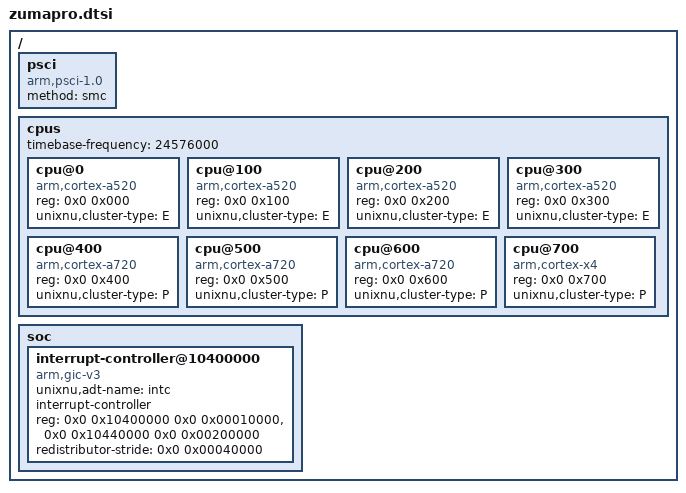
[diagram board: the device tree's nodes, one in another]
/*
 * Google Tensor G4 (zumapro).
 *
 * What is true of the chip. A board includes this and adds its own memory
 * range, framebuffer and peripherals.
 *
 * Every value was read from a Pixel 10a running stock Android, from its own
 * device tree or from the chip's registers by firmware running on it.
 */

/ {
    #address-cells = <2>;
    #size-cells = <2>;

    /* Cores are started through the secure monitor. */
    psci {
        compatible = "arm,psci-1.0";
        method = "smc";
    };

    cpus {
        #address-cells = <2>;
        #size-cells = <0>;

        /*
         * 24.576 MHz. Qualcomm boards, which most of this ecosystem is, run
         * at 19.2 MHz. A kernel told the wrong rate gets every timeout wrong
         * by a quarter and never says so.
         */
        timebase-frequency = <24576000>;

        /*
         * Four efficiency cores then four performance cores, at the affinity
         * values the phone reports. The capacities it publishes, 193 for the
         * first four and 927 or 1024 for the rest, are what splits them. The
         * first entry is the boot core.
         */
        cpu@0   { device_type = "cpu"; compatible = "arm,cortex-a520"; reg = <0x0 0x000>; unixnu,cluster-type = "E"; status = "okay"; };
        cpu@100 { device_type = "cpu"; compatible = "arm,cortex-a520"; reg = <0x0 0x100>; unixnu,cluster-type = "E"; status = "okay"; };
        cpu@200 { device_type = "cpu"; compatible = "arm,cortex-a520"; reg = <0x0 0x200>; unixnu,cluster-type = "E"; status = "okay"; };
        cpu@300 { device_type = "cpu"; compatible = "arm,cortex-a520"; reg = <0x0 0x300>; unixnu,cluster-type = "E"; status = "okay"; };
        cpu@400 { device_type = "cpu"; compatible = "arm,cortex-a720"; reg = <0x0 0x400>; unixnu,cluster-type = "P"; status = "okay"; };
        cpu@500 { device_type = "cpu"; compatible = "arm,cortex-a720"; reg = <0x0 0x500>; unixnu,cluster-type = "P"; status = "okay"; };
        cpu@600 { device_type = "cpu"; compatible = "arm,cortex-a720"; reg = <0x0 0x600>; unixnu,cluster-type = "P"; status = "okay"; };
        cpu@700 { device_type = "cpu"; compatible = "arm,cortex-x4";   reg = <0x0 0x700>; unixnu,cluster-type = "P"; status = "okay"; };
    };

    soc {
        #address-cells = <2>;
        #size-cells = <2>;
        ranges;

        /*
         * The redistributor window is 2 MiB across eight cores, so each core
         * gets 256 KiB rather than the 128 KiB of a plain GICv3. Described
         * too small, the secondary cores never start.
         */
        interrupt-controller@10400000 {
            unixnu,adt-name = "intc";
            compatible = "arm,gic-v3";
            interrupt-controller;
            #interrupt-cells = <4>;
            reg = <0x0 0x10400000 0x0 0x00010000>,
                  <0x0 0x10440000 0x0 0x00200000>;
            redistributor-stride = <0x0 0x00040000>;
            status = "okay";
        };
    };
};
